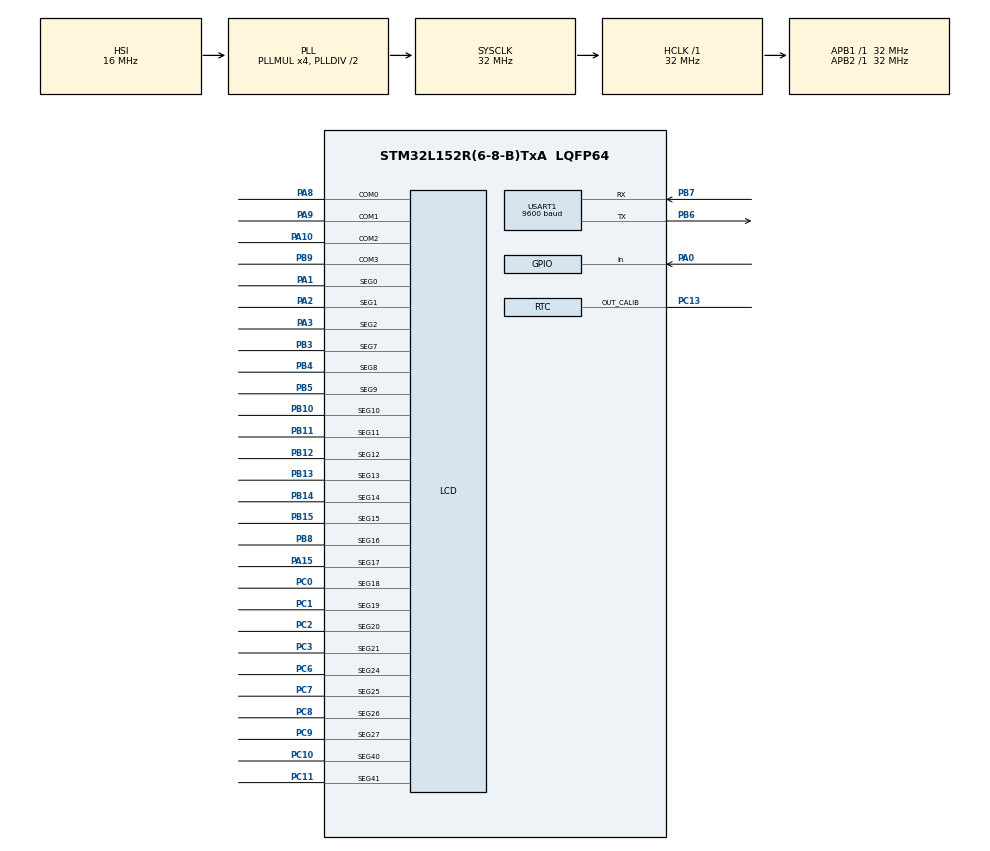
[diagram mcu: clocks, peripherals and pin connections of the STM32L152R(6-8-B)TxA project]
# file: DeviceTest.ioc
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LCD.Bias=LCD_BIAS_1_3
LCD.BlinkFrequency=LCD_BLINKFREQUENCY_DIV32
LCD.Contrast=LCD_CONTRASTLEVEL_4
LCD.PulseOnDuration=LCD_PULSEONDURATION_4
Mcu.Family=STM32L1
Mcu.Name=STM32L152R(6-8-B)TxA
Mcu.Package=LQFP64
NVIC.PriorityGroup=NVIC_PRIORITYGROUP_4
NVIC.RTC_Alarm_IRQn=true\:0\:0\:false
NVIC.USART1_IRQn=true\:0\:0\:false
PA0-WKUP1.Signal=GPIO_Input
PA1.Mode=SEG0
PA1.Signal=LCD_SEG0
PA10.Mode=1/4 Duty Cycle
PA10.Signal=LCD_COM2
PA15.Mode=SEG17
PA15.Signal=LCD_SEG17
PA2.Mode=SEG1
PA2.Signal=LCD_SEG1
PA3.Mode=SEG2
PA3.Signal=LCD_SEG2
PA8.Mode=1/4 Duty Cycle
PA8.Signal=LCD_COM0
PA9.Mode=1/4 Duty Cycle
PA9.Signal=LCD_COM1
PB10.Mode=SEG10
PB10.Signal=LCD_SEG10
PB11.Mode=SEG11
PB11.Signal=LCD_SEG11
PB12.Mode=SEG12
PB12.Signal=LCD_SEG12
PB13.Mode=SEG13
PB13.Signal=LCD_SEG13
PB14.Mode=SEG14
PB14.Signal=LCD_SEG14
PB15.Mode=SEG15
PB15.Signal=LCD_SEG15
PB3.Mode=SEG7
PB3.Signal=LCD_SEG7
PB4.Mode=SEG8
PB4.Signal=LCD_SEG8
PB5.Mode=SEG9
PB5.Signal=LCD_SEG9
PB6.Mode=Asynchronous
PB6.Signal=USART1_TX
PB7.Mode=Asynchronous
PB7.Signal=USART1_RX
PB8.Mode=SEG16
PB8.Signal=LCD_SEG16
PB9.Mode=1/4 Duty Cycle
PB9.Signal=LCD_COM3
PC0.Mode=SEG18
PC0.Signal=LCD_SEG18
PC1.Mode=SEG19
PC1.Signal=LCD_SEG19
PC10.Mode=SEG40
PC10.Signal=LCD_SEG40
PC11.Mode=SEG41
PC11.Signal=LCD_SEG41
PC13-WKUP2.Mode=Calibration_1Hz
PC13-WKUP2.Signal=RTC_OUT_CALIB
PC14-OSC32_IN.Mode=LSE-External-Oscillator
PC14-OSC32_IN.Signal=RCC_OSC32_IN
PC15-OSC32_OUT.Mode=LSE-External-Oscillator
PC15-OSC32_OUT.Signal=RCC_OSC32_OUT
PC2.Mode=SEG20
PC2.Signal=LCD_SEG20
PC3.Mode=SEG21
PC3.Signal=LCD_SEG21
PC6.Mode=SEG24
PC6.Signal=LCD_SEG24
PC7.Mode=SEG25
PC7.Signal=LCD_SEG25
PC8.Mode=SEG26
PC8.Signal=LCD_SEG26
PC9.Mode=SEG27
PC9.Signal=LCD_SEG27
ProjectManager.TargetToolchain=EWARM
RCC.AHBFreq_Value=32000000
RCC.APB1Freq_Value=32000000
RCC.APB1TimFreq_Value=32000000
RCC.APB2Freq_Value=32000000
RCC.APB2TimFreq_Value=32000000
RCC.HCLKFreq_Value=32000000
RCC.HSE_VALUE=8000000
RCC.HSI_VALUE=16000000
RCC.MSI_VALUE=2097000
RCC.PLLMUL=RCC_PLL_MUL4
RCC.RTCClockSelection=RCC_RTCCLKSOURCE_LSE
RCC.RTCClockSelectionVirtual=RCC_RTCCLKSOURCE_LSE
RCC.SYSCLKFreq_VALUE=32000000
RCC.SYSCLKSource=RCC_SYSCLKSOURCE_PLLCLK
RCC.USBOutput=32000000
RCC.VCOOutputFreq_Value=64000000
RTC.AlarmMask=RTC_ALARMMASK_ALL
RTC.Date=28
RTC.Format=FORMAT_BIN
RTC.Hours=23
RTC.Minutes=59
RTC.Seconds=50
RTC.Year=16
USART1.BaudRate=9600
VP_LCD_LCD_mux.Mode=Multiplex
VP_RTC_VS_RTC_Alarm_A_Intern.Mode=Alarm A
board=DeviceTest

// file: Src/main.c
/**
  ******************************************************************************
  * File Name          : main.c
  * Description        : Main program body
  ******************************************************************************
  *
  * COPYRIGHT(c) 2016 STMicroelectronics
  *
  * Redistribution and use in source and binary forms, with or without modification,
  * are permitted provided that the following conditions are met:
  *   1. Redistributions of source code must retain the above copyright notice,
  *      this list of conditions and the following disclaimer.
  *   2. Redistributions in binary form must reproduce the above copyright notice,
  *      this list of conditions and the following disclaimer in the documentation
  *      and/or other materials provided with the distribution.
  *   3. Neither the name of STMicroelectronics nor the names of its contributors
  *      may be used to endorse or promote products derived from this software
  *      without specific prior written permission.
  *
  * THIS SOFTWARE IS PROVIDED BY THE COPYRIGHT HOLDERS AND CONTRIBUTORS "AS IS"
  * AND ANY EXPRESS OR IMPLIED WARRANTIES, INCLUDING, BUT NOT LIMITED TO, THE
  * IMPLIED WARRANTIES OF MERCHANTABILITY AND FITNESS FOR A PARTICULAR PURPOSE ARE
  * DISCLAIMED. IN NO EVENT SHALL THE COPYRIGHT HOLDER OR CONTRIBUTORS BE LIABLE
  * FOR ANY DIRECT, INDIRECT, INCIDENTAL, SPECIAL, EXEMPLARY, OR CONSEQUENTIAL
  * DAMAGES (INCLUDING, BUT NOT LIMITED TO, PROCUREMENT OF SUBSTITUTE GOODS OR
  * SERVICES; LOSS OF USE, DATA, OR PROFITS; OR BUSINESS INTERRUPTION) HOWEVER
  * CAUSED AND ON ANY THEORY OF LIABILITY, WHETHER IN CONTRACT, STRICT LIABILITY,
  * OR TORT (INCLUDING NEGLIGENCE OR OTHERWISE) ARISING IN ANY WAY OUT OF THE USE
  * OF THIS SOFTWARE, EVEN IF ADVISED OF THE POSSIBILITY OF SUCH DAMAGE.
  *
  ******************************************************************************
  */
#include "stm32l1xx_hal.h"
#include "lcd.h"
#include "rtc.h"
#include "usart.h"
#include "gpio.h"

/* USER CODE BEGIN Includes */
#include "include.h"
#include "lcddriver.h"
/* USER CODE END Includes */

/* USER CODE BEGIN PV */
/* Private variables ---------------------------------------------------------*/

/* USER CODE END PV */

void SystemClock_Config(void);

/* USER CODE BEGIN PFP */
/* Private function prototypes -----------------------------------------------*/

/* USER CODE END PFP */

int main(void)
{

  /* MCU Configuration----------------------------------------------------------*/

  /* Reset of all peripherals, Initializes the Flash interface and the Systick. */
  HAL_Init();

  /* Configure the system clock */
  SystemClock_Config();

  /* Initialize all configured peripherals */
  MX_GPIO_Init();
  MX_LCD_Init();
  MX_RTC_Init();
  MX_USART1_UART_Init();

  /* USER CODE BEGIN 2 */
	HardInit();
	ParaInit();
  /* USER CODE END 2 */

  /* Infinite loop */
  while (1)
  {

  /* USER CODE BEGIN 3 */
	LcdDisplayHandle();
	MainHandle();
  }
  /* USER CODE END 3 */

}

/** System Clock Configuration
*/
void SystemClock_Config(void)
{

  RCC_OscInitTypeDef RCC_OscInitStruct;
  RCC_ClkInitTypeDef RCC_ClkInitStruct;
  RCC_PeriphCLKInitTypeDef PeriphClkInit;

  __PWR_CLK_ENABLE();

  __HAL_PWR_VOLTAGESCALING_CONFIG(PWR_REGULATOR_VOLTAGE_SCALE1);

  RCC_OscInitStruct.OscillatorType = RCC_OSCILLATORTYPE_HSI|RCC_OSCILLATORTYPE_LSE;
  RCC_OscInitStruct.LSEState = RCC_LSE_ON;
  RCC_OscInitStruct.HSIState = RCC_HSI_ON;
  RCC_OscInitStruct.HSICalibrationValue = 16;
  RCC_OscInitStruct.PLL.PLLState = RCC_PLL_ON;
  RCC_OscInitStruct.PLL.PLLSource = RCC_PLLSOURCE_HSI;
  RCC_OscInitStruct.PLL.PLLMUL = RCC_PLL_MUL4;
  RCC_OscInitStruct.PLL.PLLDIV = RCC_PLL_DIV2;
  HAL_RCC_OscConfig(&RCC_OscInitStruct);

  RCC_ClkInitStruct.ClockType = RCC_CLOCKTYPE_SYSCLK;
  RCC_ClkInitStruct.SYSCLKSource = RCC_SYSCLKSOURCE_PLLCLK;
  RCC_ClkInitStruct.AHBCLKDivider = RCC_SYSCLK_DIV1;
  RCC_ClkInitStruct.APB1CLKDivider = RCC_HCLK_DIV1;
  RCC_ClkInitStruct.APB2CLKDivider = RCC_HCLK_DIV1;
  HAL_RCC_ClockConfig(&RCC_ClkInitStruct, FLASH_LATENCY_1);

  PeriphClkInit.PeriphClockSelection = RCC_PERIPHCLK_RTC|RCC_PERIPHCLK_LCD;
  PeriphClkInit.RTCClockSelection = RCC_RTCCLKSOURCE_LSE;
  PeriphClkInit.LCDClockSelection = RCC_RTCCLKSOURCE_LSE;
  HAL_RCCEx_PeriphCLKConfig(&PeriphClkInit);

  HAL_SYSTICK_Config(HAL_RCC_GetHCLKFreq()/1000);

  HAL_SYSTICK_CLKSourceConfig(SYSTICK_CLKSOURCE_HCLK);

  /* SysTick_IRQn interrupt configuration */
  HAL_NVIC_SetPriority(SysTick_IRQn, 0, 0);
}

/************************ (C) COPYRIGHT STMicroelectronics *****END OF FILE****/
